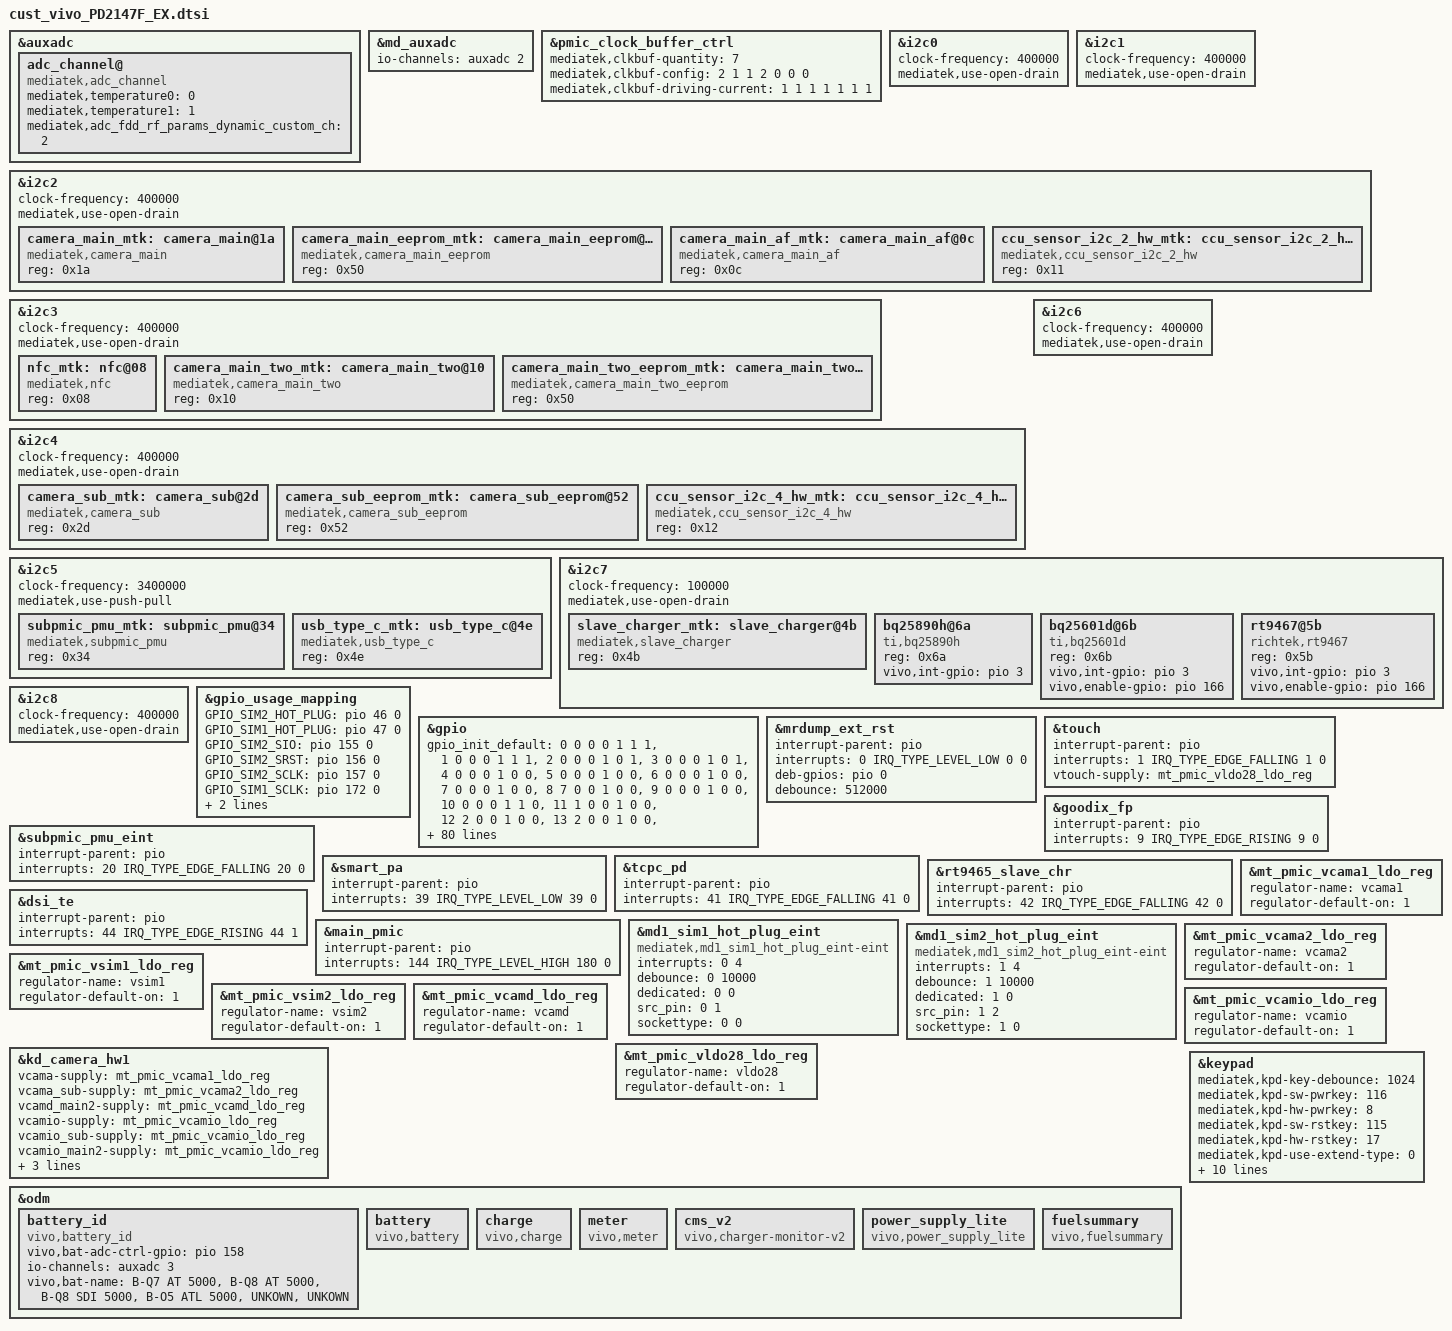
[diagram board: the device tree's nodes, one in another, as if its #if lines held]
/*
 * Generated by MTK SP DrvGen Version: 3.5.160809 for MT6768.
 * 2021-10-20 19:38:29
 * Do Not Modify The File.
 * Copyright Mediatek Inc. (c) 2016.
*/

/*************************
 * ADC DTSI File
*************************/

&auxadc {
	adc_channel@ {
		compatible = "mediatek,adc_channel";
		mediatek,temperature0 = <0>;
		mediatek,temperature1 = <1>;
		mediatek,adc_fdd_rf_params_dynamic_custom_ch = <2>;
		status = "okay";
	};
};
&md_auxadc {
	io-channels = <&auxadc 2>;
};


/*************************
 * CLK_BUF DTSI File
*************************/

&pmic_clock_buffer_ctrl {
	mediatek,clkbuf-quantity = <7>;
	mediatek,clkbuf-config = <2 1 1 2 0 0 0>;
	mediatek,clkbuf-driving-current = <1 1 1 1 1 1 1>;
	status = "okay";
};


/*************************
 * I2C DTSI File
*************************/

&i2c0 {
	#address-cells = <1>;
	#size-cells = <0>;
	clock-frequency = <400000>;
	mediatek,use-open-drain;
};

&i2c1 {
	#address-cells = <1>;
	#size-cells = <0>;
	clock-frequency = <400000>;
	mediatek,use-open-drain;
};

&i2c2 {
	#address-cells = <1>;
	#size-cells = <0>;
	clock-frequency = <400000>;
	mediatek,use-open-drain;
	camera_main_mtk:camera_main@1a {
		compatible = "mediatek,camera_main";
		reg = <0x1a>;
		status = "okay";
	};

	camera_main_eeprom_mtk:camera_main_eeprom@50 {
		compatible = "mediatek,camera_main_eeprom";
		reg = <0x50>;
		status = "okay";
	};

	camera_main_af_mtk:camera_main_af@0c {
		compatible = "mediatek,camera_main_af";
		reg = <0x0c>;
		status = "okay";
	};

	ccu_sensor_i2c_2_hw_mtk:ccu_sensor_i2c_2_hw@11 {
		compatible = "mediatek,ccu_sensor_i2c_2_hw";
		reg = <0x11>;
		status = "okay";
	};

};

&i2c3 {
	#address-cells = <1>;
	#size-cells = <0>;
	clock-frequency = <400000>;
	mediatek,use-open-drain;
	nfc_mtk:nfc@08 {
		compatible = "mediatek,nfc";
		reg = <0x08>;
		status = "okay";
	};

	camera_main_two_mtk:camera_main_two@10 {
		compatible = "mediatek,camera_main_two";
		reg = <0x10>;
		status = "okay";
	};

	camera_main_two_eeprom_mtk:camera_main_two_eeprom@50 {
		compatible = "mediatek,camera_main_two_eeprom";
		reg = <0x50>;
		status = "okay";
	};

};

&i2c4 {
	#address-cells = <1>;
	#size-cells = <0>;
	clock-frequency = <400000>;
	mediatek,use-open-drain;
	camera_sub_mtk:camera_sub@2d {
		compatible = "mediatek,camera_sub";
		reg = <0x2d>;
		status = "okay";
	};

	camera_sub_eeprom_mtk:camera_sub_eeprom@52 {
		compatible = "mediatek,camera_sub_eeprom";
		reg = <0x52>;
		status = "okay";
	};

	ccu_sensor_i2c_4_hw_mtk:ccu_sensor_i2c_4_hw@12 {
		compatible = "mediatek,ccu_sensor_i2c_4_hw";
		reg = <0x12>;
		status = "okay";
	};

};

&i2c5 {
	#address-cells = <1>;
	#size-cells = <0>;
	clock-frequency = <3400000>;
	mediatek,use-push-pull;
	subpmic_pmu_mtk:subpmic_pmu@34 {
		compatible = "mediatek,subpmic_pmu";
		reg = <0x34>;
		status = "okay";
	};

	usb_type_c_mtk:usb_type_c@4e {
		compatible = "mediatek,usb_type_c";
		reg = <0x4e>;
		status = "okay";
	};

};

&i2c6 {
	#address-cells = <1>;
	#size-cells = <0>;
	clock-frequency = <400000>;
	mediatek,use-open-drain;
};

&i2c7 {
	#address-cells = <1>;
	#size-cells = <0>;
	clock-frequency = <400000>;
	mediatek,use-open-drain;
	slave_charger_mtk:slave_charger@4b {
		compatible = "mediatek,slave_charger";
		reg = <0x4b>;
		status = "okay";
	};

};

&i2c8 {
	#address-cells = <1>;
	#size-cells = <0>;
	clock-frequency = <400000>;
	mediatek,use-open-drain;
};



/*************************
 * GPIO DTSI File
*************************/

&gpio_usage_mapping {
	GPIO_SIM2_HOT_PLUG = <&pio 46 0>;
	GPIO_SIM1_HOT_PLUG = <&pio 47 0>;
	GPIO_SIM2_SIO = <&pio 155 0>;
	GPIO_SIM2_SRST = <&pio 156 0>;
	GPIO_SIM2_SCLK = <&pio 157 0>;
	GPIO_SIM1_SCLK = <&pio 172 0>;
	GPIO_SIM1_SRST = <&pio 173 0>;
	GPIO_SIM1_SIO = <&pio 174 0>;
};

&gpio{
	gpio_init_default = <0 0 0 0 1 1 1>,
		<1 0 0 0 1 1 1>,
		<2 0 0 0 1 0 1>,
		<3 0 0 0 1 0 1>,
		<4 0 0 0 1 0 0>,
		<5 0 0 0 1 0 0>,
		<6 0 0 0 1 0 0>,
		<7 0 0 0 1 0 0>,
		<8 7 0 0 1 0 0>,
		<9 0 0 0 1 0 0>,
		<10 0 0 0 1 1 0>,
		<11 1 0 0 1 0 0>,
		<12 2 0 0 1 0 0>,
		<13 2 0 0 1 0 0>,
		<14 2 1 0 0 0 0>,
		<15 2 1 0 0 0 0>,
		<16 2 1 0 0 0 0>,
		<17 0 0 0 1 0 1>,
		<18 0 0 0 1 1 1>,
		<19 0 0 0 1 1 1>,
		<20 0 0 0 1 1 1>,
		<21 5 0 0 1 0 0>,
		<22 5 0 0 1 0 0>,
		<23 0 1 0 0 0 0>,
		<24 5 0 0 1 0 0>,
		<25 5 0 0 1 0 0>,
		<26 5 0 0 1 0 0>,
		<27 5 1 0 0 0 0>,
		<28 5 0 0 1 1 0>,
		<29 0 1 0 0 0 0>,
		<30 0 1 0 0 0 0>,
		<31 0 0 0 1 0 0>,
		<32 7 1 0 0 0 0>,
		<33 7 0 0 1 0 0>,
		<34 7 0 0 1 0 0>,
		<35 7 0 0 1 0 0>,
		<36 2 1 0 0 0 0>,
		<37 2 1 0 0 0 0>,
		<38 2 1 0 0 0 0>,
		<39 0 0 0 1 1 1>,
		<40 2 0 0 1 0 0>,
		<41 0 0 0 1 1 1>,
		<42 0 0 0 1 1 1>,
		<43 1 1 0 0 0 0>,
		<44 1 0 0 1 0 0>,
		<45 0 1 0 0 0 0>,
		<46 1 0 0 1 1 0>,
		<47 1 0 0 1 1 0>,
		<48 1 0 0 1 1 1>,
		<49 1 0 0 1 1 1>,
		<50 1 0 0 1 1 1>,
		<51 1 0 0 1 1 1>,
		<52 1 0 0 1 0 0>,
		<53 1 0 0 1 0 0>,
		<54 1 0 0 1 0 0>,
		<55 1 0 0 1 0 0>,
		<56 1 0 0 1 0 0>,
		<57 1 0 0 1 0 0>,
		<58 0 0 0 1 0 0>,
		<59 1 0 0 1 0 0>,
		<60 1 0 0 1 0 0>,
		<61 1 0 0 1 0 0>,
		<62 1 0 0 1 0 0>,
		<63 1 0 0 1 0 0>,
		<64 1 0 0 1 0 0>,
		<65 1 0 0 1 0 0>,
		<66 1 0 0 1 0 0>,
		<67 1 0 0 1 0 0>,
		<68 1 0 0 1 0 0>,
		<69 1 0 0 1 0 0>,
		<70 1 0 0 1 0 0>,
		<71 1 0 0 1 0 0>,
		<72 1 0 0 1 0 0>,
		<73 1 0 0 1 0 0>,
		<74 1 0 0 1 0 0>,
		<75 1 0 0 1 0 0>,
		<76 1 0 0 1 0 0>,
		<77 1 0 0 1 0 0>,
		<78 1 0 0 1 0 0>,
		<79 0 0 0 1 0 0>,
		<80 0 0 0 1 0 0>,
		<81 2 0 0 1 1 1>,
		<82 1 0 0 1 1 1>,
		<83 1 0 0 1 1 1>,
		<84 2 0 0 1 1 1>,
		<85 2 0 0 1 0 0>,
		<86 2 1 0 0 0 0>,
		<87 2 1 0 0 0 0>,
		<88 2 1 0 0 0 0>,
		<89 1 0 0 1 1 1>,
		<90 1 0 0 1 1 1>,
		<91 0 0 0 0 0 0>,
		<92 1 1 0 0 0 0>,
		<93 1 0 0 1 1 0>,
		<94 0 1 0 0 0 0>,
		<95 1 0 0 1 1 0>,
		<96 1 1 0 0 0 0>,
		<97 0 1 0 0 0 0>,
		<98 0 1 0 0 0 0>,
		<99 1 1 0 0 0 0>,
		<100 1 1 0 0 0 0>,
		<101 0 1 0 0 0 0>,
		<102 0 1 0 0 0 0>,
		<103 1 0 0 1 1 1>,
		<104 1 0 0 1 1 1>,
		<105 1 0 0 1 1 1>,
		<106 1 0 0 1 1 1>,
		<107 0 1 0 0 0 0>,
		<108 0 0 0 0 0 0>,
		<109 0 1 0 0 0 0>,
		<110 0 1 0 0 0 0>,
		<111 1 1 0 0 0 0>,
		<112 0 0 0 0 0 0>,
		<113 0 0 0 1 0 0>,
		<114 0 0 0 1 0 0>,
		<115 0 0 0 1 0 0>,
		<116 0 0 0 1 0 0>,
		<117 0 0 0 1 0 0>,
		<118 0 0 0 1 0 0>,
		<119 0 0 0 1 0 0>,
		<120 0 0 0 1 0 0>,
		<121 0 0 0 1 0 0>,
		<134 1 0 0 1 0 1>,
		<135 1 1 0 0 0 0>,
		<136 1 1 0 0 0 0>,
		<137 1 1 0 0 0 0>,
		<138 1 1 0 0 0 0>,
		<139 1 1 0 0 0 0>,
		<140 1 0 0 1 0 0>,
		<141 1 0 0 1 0 0>,
		<142 1 0 0 1 0 0>,
		<143 1 0 0 1 0 0>,
		<144 1 0 0 1 0 0>,
		<145 1 1 0 0 0 0>,
		<146 1 1 0 0 0 0>,
		<147 1 1 0 0 0 0>,
		<148 1 1 0 0 0 0>,
		<149 1 1 0 0 0 0>,
		<150 4 0 0 1 1 0>,
		<151 4 1 0 0 0 0>,
		<152 5 0 0 1 1 0>,
		<153 5 1 0 0 0 0>,
		<154 1 1 0 0 0 0>,
		<155 1 0 0 1 1 0>,
		<156 1 1 0 0 0 0>,
		<157 1 1 0 0 0 0>,
		<158 1 1 0 0 0 0>,
		<159 0 1 0 0 0 0>,
		<160 0 1 0 0 0 0>,
		<161 1 0 0 1 1 1>,
		<162 1 0 0 1 1 1>,
		<163 1 0 0 1 1 1>,
		<164 1 0 0 1 1 1>,
		<165 4 0 0 1 1 0>,
		<166 0 1 0 0 0 0>,
		<167 1 0 0 1 0 0>,
		<168 1 0 0 1 0 0>,
		<169 4 1 0 0 0 0>,
		<170 1 0 0 1 1 1>,
		<171 1 1 0 0 0 1>,
		<172 1 1 0 0 0 0>,
		<173 1 1 0 0 0 0>,
		<174 1 0 0 1 1 0>,
		<175 1 0 0 1 1 1>,
		<176 1 0 0 1 1 1>,
		<178 0 1 0 0 0 0>,
		<179 0 1 0 0 0 0>,
		<180 0 0 0 1 0 0>,
		<181 0 0 0 1 0 0>,
		<182 0 0 0 1 0 0>,
		<183 0 0 0 1 0 0>,
		<184 0 0 0 1 0 0>,
		<185 0 0 0 1 0 0>,
		<186 0 0 0 1 0 0>;
};


/*************************
 * EINT DTSI File
*************************/

#include <dt-bindings/interrupt-controller/irq.h>
#include <dt-bindings/interrupt-controller/arm-gic.h>

&mrdump_ext_rst {
	interrupt-parent = <&pio>;
	interrupts = <0 IRQ_TYPE_LEVEL_LOW 0 0>;
	deb-gpios = <&pio 0 0>;
	debounce = <512000>;
	status = "okay";
};

&touch {
	interrupt-parent = <&pio>;
	interrupts = <1 IRQ_TYPE_EDGE_FALLING 1 0>;
	status = "okay";
};

&goodix_fp {
	interrupt-parent = <&pio>;
	interrupts = <9 IRQ_TYPE_EDGE_RISING 9 0>;
	status = "okay";
};

&subpmic_pmu_eint {
	interrupt-parent = <&pio>;
	interrupts = <20 IRQ_TYPE_EDGE_FALLING 20 0>;
	status = "okay";
};

&smart_pa {
	interrupt-parent = <&pio>;
	interrupts = <39 IRQ_TYPE_LEVEL_LOW 39 0>;
	status = "okay";
};

&tcpc_pd {
	interrupt-parent = <&pio>;
	interrupts = <41 IRQ_TYPE_EDGE_FALLING 41 0>;
	status = "okay";
};

&rt9465_slave_chr {
	interrupt-parent = <&pio>;
	interrupts = <42 IRQ_TYPE_EDGE_FALLING 42 0>;
	status = "okay";
};

&dsi_te {
	interrupt-parent = <&pio>;
	interrupts = <44 IRQ_TYPE_EDGE_RISING 44 1>;
	status = "okay";
};

&main_pmic {
	interrupt-parent = <&pio>;
	interrupts = <144 IRQ_TYPE_LEVEL_HIGH 180 0>;
	status = "okay";
};



/*************************
 * MD1_EINT DTSI File
*************************/

&md1_sim1_hot_plug_eint {
	compatible = "mediatek,md1_sim1_hot_plug_eint-eint";
	interrupts = <0 4>;
	debounce = <0 10000>;
	dedicated = <0 0>;
	src_pin = <0 1>;
	sockettype = <0 0>;
	status = "okay";
};

&md1_sim2_hot_plug_eint {
	compatible = "mediatek,md1_sim2_hot_plug_eint-eint";
	interrupts = <1 4>;
	debounce = <1 10000>;
	dedicated = <1 0>;
	src_pin = <1 2>;
	sockettype = <1 0>;
	status = "okay";
};



/*************************
 * PMIC DTSI File
*************************/

&mt_pmic_vcama1_ldo_reg {
	regulator-name = "vcama1";
	regulator-default-on = <1>; /* 0:skip, 1: off, 2:on */
	status = "okay";
};
&mt_pmic_vcama2_ldo_reg {
	regulator-name = "vcama2";
	regulator-default-on = <1>; /* 0:skip, 1: off, 2:on */
	status = "okay";
};
&mt_pmic_vsim1_ldo_reg {
	regulator-name = "vsim1";
	regulator-default-on = <1>; /* 0:skip, 1: off, 2:on */
	status = "okay";
};
&mt_pmic_vsim2_ldo_reg {
	regulator-name = "vsim2";
	regulator-default-on = <1>; /* 0:skip, 1: off, 2:on */
	status = "okay";
};
&mt_pmic_vcamd_ldo_reg {
	regulator-name = "vcamd";
	regulator-default-on = <1>; /* 0:skip, 1: off, 2:on */
	status = "okay";
};
&mt_pmic_vcamio_ldo_reg {
	regulator-name = "vcamio";
	regulator-default-on = <1>; /* 0:skip, 1: off, 2:on */
	status = "okay";
};
&mt_pmic_vldo28_ldo_reg {
	regulator-name = "vldo28";
	regulator-default-on = <1>; /* 0:skip, 1: off, 2:on */
	status = "okay";
};

&kd_camera_hw1 {
	vcama-supply = <&mt_pmic_vcama1_ldo_reg>;
	vcama_sub-supply = <&mt_pmic_vcama2_ldo_reg>;
	vcamd_main2-supply = <&mt_pmic_vcamd_ldo_reg>;
	vcamio-supply = <&mt_pmic_vcamio_ldo_reg>;
	vcamio_sub-supply = <&mt_pmic_vcamio_ldo_reg>;
	vcamio_main2-supply = <&mt_pmic_vcamio_ldo_reg>;
	vcamaf-supply = <&mt_pmic_vldo28_ldo_reg>;
	vcamaf_sub-supply = <&mt_pmic_vldo28_ldo_reg>;
	vcamaf_main2-supply = <&mt_pmic_vldo28_ldo_reg>;
	status = "okay";
};

&touch {
	vtouch-supply = <&mt_pmic_vldo28_ldo_reg>;
	status = "okay";
};


/*************************
 * POWER DTSI File
*************************/

/* fuxi add for battery&charge start */
#ifdef CONFIG_VIVO_CHARGING_NEW_ARCH
#ifdef CONFIG_VIVO_CHARGING_DTS_MOVE_HEAD_FILE
&odm {
	battery_id {
		compatible = "vivo,battery_id";
		status = "okay";

		vivo,bat-adc-ctrl-gpio = <&pio 158 0>;

		io-channels = <&auxadc 3>;
		io-channel-names = "battery_id_adc";

		vivo,bat-name = "B-Q7 AT 5000","B-Q8 AT 5000","B-Q8 SDI 5000","B-O5 ATL 5000","UNKOWN","UNKOWN";
	};

	battery: battery {
		compatible = "vivo,battery";
		status = "okay";
	};

	charge: charge {
		compatible = "vivo,charge";
		status = "okay";
	};

	meter: meter {
		compatible = "vivo,meter";
		status = "okay";
	};

	cms_v2: cms_v2 {
		compatible = "vivo,charger-monitor-v2";
		status = "okay";
	};

	power_supply_lite: power_supply_lite {
		compatible = "vivo,power_supply_lite";
		status = "okay";
	};

	fuelsummary: fuelsummary {
		compatible = "vivo,fuelsummary";
		status = "okay";
	};
};

#else

&battery_id {
	status = "okay";
	compatible = "vivo,battery_id";

	vivo,bat-adc-ctrl-gpio = <&pio 158 0>;

	io-channels = <&auxadc 3>;
	io-channel-names = "battery_id_adc";

	vivo,bat-name = "B-S2 ATL 5000","B-S1 LW 5000","B-S2 ATL 5000","B-S3 ATL 5000","UNKOWN","UNKOWN";
};

&battery {
	status = "okay";
	compatible = "vivo,battery";

	io-channels = <&auxadc 0>,
		<&auxadc 1>,
		<&auxadc 2>;
	io-channel-names = "primary_board_therm",
		"pa_therm",
		"parallel_board_therm";

	vivo,low-volt-threshold = <3400>;
	vivo,soft-rise-percent = <96>;
	vivo,soft-rise-cumulative = <3>;
	vivo,soft-rise-keep-cumulative = <10>;
	vivo,percnet-sync-delta = <8>;
	vivo,percnet-sync-cumulative = <9>;
	vivo,full-sync-cumulative = <3>;
	vivo,soft-term-percent = <99>;
	vivo,soft-term-cumulative = <30>;
};

&charge {
	status = "okay";
	compatible = "vivo,charge";

	vivo,chg-wdt-s = <40>;
	vivo,re-chg-voltage-mv = <100>;
	vivo,prechg-voltage-mv = <3000>;
	vivo,iprechg-current-ma = <300>;
	vivo,iterm-current-ma = <256>;
	vivo,vreg-voltage-mv = <4430>;
	vivo,vindpm-voltage-mv = <4600>;
	vivo,sys-voltage-min-mv= <3300>;
	vivo,boostv-voltage-mv = <5150>;
	vivo,boostv-ilimit-ma = <1500>;
	vivo,ovp-voltage-mv = <15000>;

	/*
	 * 0  auto detect charging
	 * 1  vivo-normal chargine
	 * 2  vivo-single engine charging
	 * 3  vivo-dual engine charging
	 * 4  vivo-flash charging
	 */
	vivo,charge-scheme = <0>;
	vivo,direct-charger-enable;

	/*
	 * SUPPORTED_ADAPTER_DEFAULT = 0,
	 * SUPPORTED_ADAPTER_VIVO_LV_DCHG_5V_4500MA = 1,
	 * SUPPORTED_ADAPTER_VIVO_HV_DCHG_10V_2250MA = 2,
	 * SUPPORTED_ADAPTER_QC20__9V_2000MA = 3,
	 * SUPPORTED_ADAPTER_VIVO_HV_DCHG_10V_4000MA = 4,
	 * SUPPORTED_ADAPTER_MAX,
	 */
	vivo,supported-adapter = <3>;

	//parameter for 9V2A
	vivo,primary-ichg-max-ma = <2240>;
	vivo,parallel-ichg-max-ma = <1680>;

	vivo,flashchg-spec-ma = <2000 3300 6000>;
	vivo,fastchg-spec-ma = <2000 2100 3800>;
	vivo,normalchg-spec-ma = <2000 1500 2300>;

	/* 0---PMIC; 1---CHGIC */
	vivo,vbus-detect-source = <1>;

	//vivo,usboe-gpio = <&pio 178 0>;

	/*ffc*/
	//vivo,ffc-enable;
	vivo,ffc-iterm-ma = <(-750)>;
	vivo,ffc-vreg-mv = <4500>;
	vivo,ffc-temperature-range = <150 450>;
	vivo,ffc-full-vbat-table-size = <3>;
	vivo,ffc-full-vbat-table = <4498 4500 4490>;
	vivo,ffc-full-ibat-table-size = <3>;
	vivo,ffc-full-ibat-table = <150 199 (-854)>,
		<200 349 (-1122)>,
		<350 449 (-1268)>;

	/*otg reverse chg*/
	//vivo,otg-reverse-chg-support;
	vivo,otg-reverse-i-table-size = <5>;
	vivo,otg-reverse-i-table = <471 8888 800 1000>,
		<441 470 1200 1400>,
		<411 440 1600 1800>,
		<0 410 1800 2000>,
		<(-8888) 0 900 1100>;
};

&meter {
	status = "okay";
	compatible = "vivo,meter";

	vivo,load-capacity-delta-max = <60>;
	vivo,poweron-delta-capacity = <20>;
	vivo,poweron-low-capacity = <3>;
	vivo,volt-car-delta = <10>;
	vivo,car-volt-delta = <8>;
	vivo,meter-res-compesate = <10>;
	vivo,ocv-board-compesate = <0>;

	/* 0---AGING_UNSUPPORTED; 1---DRIVER_SUPPORTED; 2---USPACE_SUPPORTED */
	vivo,battery-aging-support = <2>;

	vivo,capacity-mAh = <4910>;
	/*COLD_CHG COLD_DISCHG NORMAL_CHG NORMAL_DISCHG*/
	vivo,car-tune-value = <1000 990 1000 1000>,
		<1030 1000 1005 1000>,
		<1000 990 1000 1000>,
		<1000 1000 1000 1000>,
		<1000 1000 1000 1000>,
		<1000 1000 1000 1000>;
	vivo,bats-qmax = <4360 4429 4916 4990 4988>,
		<3340 3950 4500 4590 4660>,
		<4360 4429 4916 4990 4988>,
		<3900 4281 4605 4648 4690>,
		<4500 4668 4762 4851 4821>,
		<4500 4668 4762 4851 4821>;

	/* car-tune adjust remap */
	vivo,car-tune-adjust-enable;
	vivo,car-tune-adjust-size = <3>;
	vivo,car-tune-adjust-table = <0 10 (330) 6>,
		<11 20 (-30) 7>,
		<21 100 (-30) 8>;

	#include "bat_setting/PD2138_battery_table.dtsi"
};

&cms_v2 {
	compatible = "vivo,charger-monitor-v2";
	status = "okay";

	default_board: single_charger_board {
		       /*default board: keep in xxxxxx*/
		       support-board-version = "xxxxxx";

		       vivo,bat-det-method = <0>;//r:0, rc:1, eprom:2, ex-fg:3
		       //vivo,bat-id-gpio = <&pio 159 0>;

		       /*
			  CHG0__CHARGING_TECHNOLOGY_NONE = 0,
			  CHG1__NORMAL_CHARGING,			//5V/2A normal charging
			  CHG2__QC2_CHARGING,				//9V/2A	QC2.0 charging
			  CHG3__LOW_VOLTAGE_DIRECT_CHARGING,		//5V/4.5A direct charging
			  CHG4__SINGLE_IC_DIV2_CHARGING,		//single IC Div/2 charging
			  CHG5__DUAL_IC_DIV2_CHARGING,			//Dual IC Div/2 charging
			  CHG6__DUAL_IC_DUAL_BATTERY_DIV2_CHARGING,	//Dual IC Div/2 charging
			  CHGX__CHARGING_TECHNOLOGY_MAX,
			*/
		       vivo,charging-technology = <2>;

		       //vivo,no-bat-warning;
		       //vivo,no-chg-timeout;
		       vivo,chg-timeout-mins = <900>;

		       //high temperature charger current control enable
		       vivo,htccc-enable;
		       vivo,htccc-data = <46 55 4100000 100000>;

		       //vivo,fbon-scale-enable;/*disable default*/
		       vivo,fbon-scale-data = <2 100 100>;

		       //vivo,switch-scale-enable;/*disable from rom4.0*/
		       vivo,switch-scale-data = <75 53>;

		       vivo,calling-scale-enable;
		       vivo,calling-scale-data = <100 21>;/*ibat:3900 * 0.54 = 2106,more than 1500,not exit dchg*/
		       vivo,calling-dchg-disable;

		       vivo,weixin-calling-scale-enable;
		       vivo,weixin-calling-scale-data = <100 104>;/*5000mA*/

		       //vivo,fixed-scale-enable;
		       vivo,fixed-scale-data = <120 3800 0>;/*dchg fixed time adjust the max ibat,disable default*/

		       /*data processing : batt-temp*/
		       vivo,dp-batt-temp-enable;
		       vivo,dp-batt-temp-data = <100>;

		       /* charging current for devices in exhibition mode */
		       vivo,exhibition-mode-current-primary = <2048>;
		       vivo,exhibition-mode-current-parallel = <0>;

		       /*default tc parameter*/
		       //single charger ibat scale base on temperature battery cell info:1C/1.2C 3960mah
		       /* tmin, tmax, data, volt1, data_ex1, volt2, data_ex2. */
		       vivo,normal-tc-row-col = <10 9>;
		       vivo,normal-tc-data = <550 8888 0 0 0 0 0 0 0>,
			       <450 549 50 0 0 0 0 0 0>,
			       <200 449 100 4200000 70 0 0 0 0>,
			       <150 199 100 4200000 70 0 0 0 0>,
			       <100 149 70 4200000 50 0 0 0 0>,
			       <50 99 50 4200000 30 0 0 0 0>,
			       <0 49 50 4200000 30 0 0 0 0>,
			       <(-8888) (-1) 0 0 0 0 0 0 0>,
			       <(-8888) (-1) 0 0 0 0 0 0 0>,
			       <(-8888) (-1) 0 0 0 0 0 0 0>;

		       /*flash tc parameter*/
		       vivo,flash-normal-tc-row-col = <10 9>;
		       vivo,flash-normal-tc-data = <550 8888 0 0 0 0 0 0 0>,
			       <450 549 50 0 0 0 0 0 0>,
			       <350 449 123 4430000 87 0 0 0 0>,
			       <200 349 123 4430000 87 0 0 0 0>,
			       <150 199 123 4300000 102 4430000 80 0 0>,
			       <100 149 100 0 0 0 0 0 0>,
			       <50 99 70 4200000 50 0 0 0 0>,
			       <0 49 70 4200000 50 0 0 0 0>,
			       <(-50) (-1) 0 0 0 0 0 0 0>,
			       <(-8888) (-51) 0 0 0 0 0 0 0>;

		       /*adjust fastchg base on board temperature and fb off*/
		       vivo,intell-charge-enable;
		       vivo,parallel-temp-enable = <1 1>;//<x y> x:fb-on y:fb-off

		       /* Flash charge fb-on intell param */
		       vivo,primary-fbon-tc-row-col = <7 3>;
		       vivo,primary-fbon-tc-data = <471 8888 1500>,
			       <461 470 2600>,
			       <441 460 3050>,
			       <426 440 3800>,
			       <416 425 4300>,
			       <396 415 4800>,
			       <(-8888) 395 5200>;

		       vivo,parallel-fbon-tc-row-col = <1 3>;
		       vivo,parallel-fbon-tc-data = <(-8888) 8888 0>;

		       /* Flash charge fb-off intell param */
		       vivo,primary-fboff-tc-row-col = <6 3>;
		       vivo,primary-fboff-tc-data = <418 8888 1600>,
			       <391 417 2800>,
			       <381 390 4000>,
			       <371 380 4200>,
			       <361 370 4800>,
			       <(-8888) 360 5800>;
		       vivo,parallel-fboff-tc-row-col = <1 3>;
		       vivo,parallel-fboff-tc-data = <(-8888) 8888 0>;

		       /* 9v Fast charge fb-on intell param */
		       vivo,9v-primary-fbon-tc-row-col = <6 3>;
		       vivo,9v-primary-fbon-tc-data = <466 8888 300>,
			       <456 465 400>,
			       <426 455 1100>,
			       <411 425 1300>,
			       <381 410 1400>,
			       <(-8888) 380 1600>;
		       vivo,9v-parallel-fbon-tc-row-col = <6 3>;
		       vivo,9v-parallel-fbon-tc-data = <451 8888 0>,
			       <421 450 700>,
			       <401 420 900>,
			       <391 400 1100>,
			       <371 390 1300>,
			       <(-8888) 370 1500>;
		       // second parallel parameter, for rt9467
		       vivo,9v-2nd-parallel-fbon-tc-row-col = <6 3>;
		       vivo,9v-2nd-parallel-fbon-tc-data = <450 8888 500>,
			       <430 449 800>,
			       <440 429 1000>,
			       <390 399 1100>,
			       <370 389 1300>,
			       <(-8888) 369 1500>;


		       /* 9v Fast charge fb-off intell param */
		       vivo,9v-primary-fboff-tc-row-col = <7 3>;
		       vivo,9v-primary-fboff-tc-data = <436 8888 300>,
			       <426 435 500>,
			       <401 425 1300>,
			       <386 400 1500>,
			       <371 385 1700>,
			       <361 370 1850>,
			       <(-8888) 360 2000>;
		       vivo,9v-parallel-fboff-tc-row-col = <6 3>;
		       vivo,9v-parallel-fboff-tc-data = <436 8888 0>,
			       <426 435 800>,
			       <401 425 1000>,
			       <386 400 1200>,
			       <371 385 1400>,
			       <(-8888) 370 1600>;
		       // second parallel parameter, for rt9467
		       vivo,9v-2nd-parallel-fboff-tc-row-col = <7 3>;
		       vivo,9v-2nd-parallel-fboff-tc-data = <430 8888 500>,
			       <405 429 1200>,
			       <390 404 1300>,
			       <380 389 1500>,
			       <370 379 1550>,
			       <360 369 1700>,
			       <(-8888) 359 1800>;


		       /* 5v Normal charge fb-on intell param */
		       vivo,5v-primary-fbon-tc-row-col = <7 3>;
		       vivo,5v-primary-fbon-tc-data = <491 8888 512>,
			       <471 490 1024>,
			       <451 470 1216>,
			       <431 450 1408>,
			       <411 430 1600>,
			       <381 410 1800>,
			       <(-8888) 380 2048>;
		       vivo,5v-parallel-fbon-tc-row-col = <1 3>;
		       vivo,5v-parallel-fbon-tc-data = <(-8888) 8888 0>;

		       /* 5v Normal charge fb-off intell param */
		       vivo,5v-primary-fboff-tc-row-col = <6 3>;
		       vivo,5v-primary-fboff-tc-data = <491 8888 512>,
			       <471 490 1024>,
			       <451 470 1216>,
			       <431 450 1600>,
			       <411 430 1800>,
			       <(-8888) 410 2304>;
		       vivo,5v-parallel-fboff-tc-row-col = <1 3>;
		       vivo,5v-parallel-fboff-tc-data = <(-8888) 8888 0>;

		       // Direct charging param
		       vivo,direct-charger-enable;//porting_check
		       vivo,ex-bms-psy-name = "bq_bms";

		       // bat_baord, usb_conn, pcb_conn(master_bat_conn), bat_conn
		       vivo,dchg-ntc-protect-enable;
		       vivo,dchg-ntc-protect-data = <750 800 850 850>;

		       vivo,adapter-cooldown-data = <900 850 3400>;
		       /*adapter power derate*/
		       vivo,adapter-power-derate-enable;

		       /* usb connecter protect param
			* USB_PROTECT_NONE = 0,
			* USB_CONN_TEMP_HEAT_PROTECT = BIT(0),
			* USB_ID_PROTECT = BIT(1),
			*/
		       vivo,usb-connecter-protect-enable = <1>;
		       vivo,usb-id-protect-data= <1100 1547 500>;/* 500K, 2M, fcc */
		       vivo,usb-conn-heat-protect-data-row-col = <2 4>;
		       vivo,usb-conn-heat-protect-data= <260 8888 670 620>,
			       <(-8888) 259 570 520>;

		       /*
			* max vbus of adapter:11v, max ibus of adapter:5A
			* min voltage of battery for half chg:3500mV,max voltage of battery for half charge:4100mV,
			* 5V2A charge min current threshold: 1000mA,5V2A charge max current threshold:2100mA,
			* flash charge min current threshold:5000mA,flash charge max current threshold:11000mA
			*/

		       /*default parameter*/
		       vivo,charge-param-judge-threshold = <9 2 3500 4300 1000 2100 2100 4600>;
		       /* factory mode charging test param */
		       vivo,charge-test-param-row-col = <12 3>;
		       vivo,charge-test-param-data = <0 0 5500>, /* cable resistance, min value, max value */
			       <0 0 5500>, /* master ibus, min ibus, max ibus */
			       <0 0 5500>, /* slave ibus, min ibus, max ibus */
			       <1 20 40>, /* batt therm ntc, min value, max value */
			       <1 20 45>, /* board therm ntc, min value, max value */
			       <0 20 50>, /* sub charger ntc, min value, max value */
			       <0 20 45>, /* usb con ntc, min value, max value */
			       <0 20 45>, /* usb con 1 ntc, double usb NTC, min value, max value */
			       <0 20 45>, /* bat btb master ntc, min value, max value */
			       <0 20 50>, /* bat btb sub ntc, min value, max value */
			       <0 20 50>, /* bat board ntc, min value, max value */
			       <0 20 50>; /* wireless charge coil ntc, min value, max value */

		       /*flash parameter*/
		       vivo,flash-charge-param-judge-threshold = <11 3 3500 4100 1000 2200 4000 6100>;
		       /* factory mode charging test param */
		       vivo,flash-charge-test-param-row-col = <12 3>;
		       vivo,flash-charge-test-param-data = <1 0 5500>, /* cable resistance, min value, max value */
			       <1 0 5500>, /* master ibus, min ibus, max ibus */
			       <0 0 5500>, /* slave ibus, min ibus, max ibus */
			       <1 20 40>, /* batt therm ntc, min value, max value */
			       <1 20 45>, /* board therm ntc, min value, max value */
			       <0 20 50>, /* sub charger ntc, min value, max value */
			       <1 20 45>, /* usb con ntc, min value, max value */
			       <0 20 45>, /* usb con 1 ntc, double usb NTC, min value, max value */
			       <1 20 45>, /* bat btb master ntc, min value, max value */
			       <0 20 50>, /* bat btb sub ntc, min value, max value */
			       <0 20 50>, /* bat board ntc, min value, max value */
			       <0 20 50>; /* wireless charge coil ntc, min value, max value */
			#include "bat_setting/PD2138_battery_chg_params.dtsi"
		};
};

&power_supply_lite {
	status = "okay";
	compatible = "vivo,power_supply_lite";
};

&fuelsummary {
	status = "okay";
	compatible = "vivo,fuelsummary";

	/************************************************************
	 *
	 *  0   vivo-fastchg
	 *  1   qcom-dualchg
	 *  2   mtk-dualchg
	 *  3   qcom-normchg
	 *  4   mtk-normchg
	 *
	 ***********************************************************/
	chg-scheme = <2>;
	fex-version = <3>;
	fbon-ibat = <(-900)>;
	fboff-ibat = <(-1000)>;

	/* 0---AGING_UNSUPPORTED; 1---DRIVER_SUPPORTED; 2---USPACE_SUPPORTED */
	vivo,battery-aging-support = <2>;
};

#endif

&i2c7 {
	#address-cells = <1>;
	#size-cells = <0>;
	status = "okay";
	clock-frequency = <100000>;

	bq25890h@6a {
		compatible = "ti,bq25890h";
		reg = <0x6a>;

		vivo,int-gpio = <&pio 3 0>;
	};

	bq25601d@6b {
		compatible = "ti,bq25601d";
		reg = <0x6b>;

		vivo,int-gpio = <&pio 3 0>;
		vivo,enable-gpio = <&pio 166 0>;
		//vivo,chg-version-gpio = <&pio 77 0>;
	};

	rt9467@5b {
		compatible = "richtek,rt9467";
		reg = <0x5b>;

		vivo,int-gpio = <&pio 3 0>;
		vivo,enable-gpio = <&pio 166 0>;
		//vivo,chg-version-gpio = <&pio 77 0>;
	};
};
#endif
/* fuxi add for battery&charge end */



/*************************
 * KPD DTSI File
*************************/

&keypad {
	mediatek,kpd-key-debounce = <1024>;
	mediatek,kpd-sw-pwrkey = <116>;
	mediatek,kpd-hw-pwrkey = <8>;
	mediatek,kpd-sw-rstkey  = <115>;
	mediatek,kpd-hw-rstkey = <17>;
	mediatek,kpd-use-extend-type = <0>;
	/*HW Keycode [0~71] -> Linux Keycode*/
	mediatek,kpd-hw-map-num = <72>;
	mediatek,kpd-hw-init-map = <114 0 0 0 0 0 0 0 0 0 0 0 0 0 0 0 0 0 0 0 0 0 0 0 0 0 0 0 0 0 0 0 0 0 0 0 0 0 0 0 0 0 0 0 0 0 0 0 0 0 0 0 0 0 0 0 0 0 0 0 0 0 0 0 0 0 0 0 0 0 0 0 >;
	mediatek,kpd-pwrkey-eint-gpio = <0>;
	mediatek,kpd-pwkey-gpio-din  = <0>;
	mediatek,kpd-hw-dl-key0 = <17>;
	mediatek,kpd-hw-dl-key1 = <0>;
	mediatek,kpd-hw-dl-key2 = <8>;
	mediatek,kpd-hw-recovery-key = <17>;
	mediatek,kpd-hw-factory-key = <0>;
	status = "okay";
};


